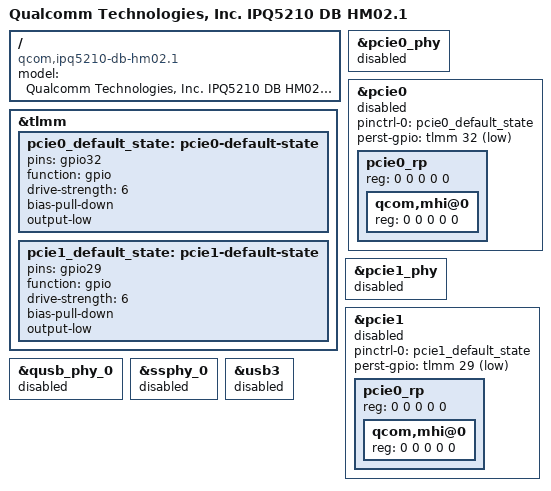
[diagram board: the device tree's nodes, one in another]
// SPDX-License-Identifier: (GPL-2.0+ OR BSD-3-Clause)
/*
 * IPQ5210 DB HM02.1 board device tree source
 *
 * Copyright (c) 2020-2021 The Linux Foundation. All rights reserved.
 * Copyright (c) Qualcomm Technologies, Inc. and/or its subsidiaries.
 */

/dts-v1/;

#include "ipq5210-rdp-common.dtsi"

/ {
	model = "Qualcomm Technologies, Inc. IPQ5210 DB HM02.1";
	compatible = "qcom,ipq5210-db-hm02.1", "qcom,ipq5210";
};

&tlmm {
	pcie0_default_state: pcie0-default-state {
		pins = "gpio32";
		function = "gpio";
		drive-strength = <6>;
		bias-pull-down;
		output-low;
	};

	pcie1_default_state: pcie1-default-state {
		pins = "gpio29";
		function = "gpio";
		drive-strength = <6>;
		bias-pull-down;
		output-low;
	};
};

&pcie0_phy {
	status = "disabled";
};

&pcie0 {
	pinctrl-0 = <&pcie0_default_state>;
	perst-gpio = <&tlmm 32 GPIO_ACTIVE_LOW>;
	status = "disabled";

	pcie0_rp {
		reg = <0 0 0 0 0>;
		qcom,mhi@0 {
			reg = <0 0 0 0 0>;
		};
	};
};

&pcie1_phy {
	status = "disabled";
};

&pcie1 {
	pinctrl-0 = <&pcie1_default_state>;
	perst-gpio = <&tlmm 29 GPIO_ACTIVE_LOW>;
	status = "disabled";

	pcie0_rp {
		reg = <0 0 0 0 0>;
		qcom,mhi@0 {
			reg = <0 0 0 0 0>;
		};
	};
};

&qusb_phy_0 {
	status = "disabled";
};

&ssphy_0 {
	status = "disabled";
};

&usb3 {
	status = "disabled";
};
